VERSION ""

NS_ :

BS_:

BU_:

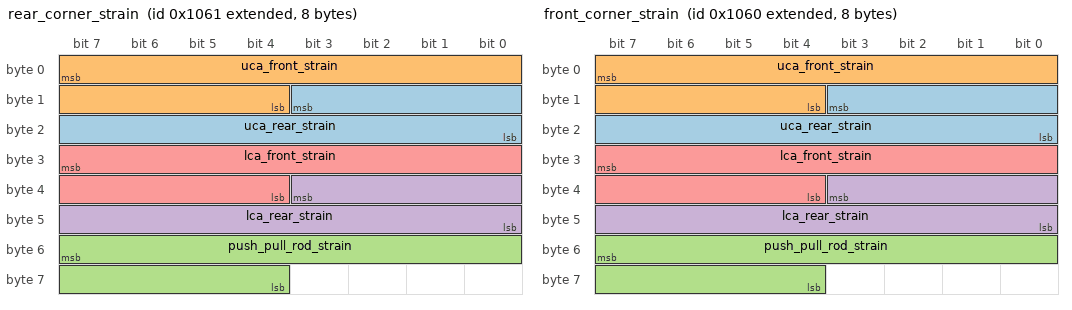
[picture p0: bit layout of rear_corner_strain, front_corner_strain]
BO_ 2147487841 rear_corner_strain: 8 Vector__XXX
 SG_ uca_rear_strain : 11|12@0+ (0.00488758553274682,0) [0|0] "V" Vector__XXX
 SG_ uca_front_strain : 7|12@0+ (0.00488758553274682,0) [0|0] "V" Vector__XXX
 SG_ push_pull_rod_strain : 55|12@0+ (0.00488758553274682,0) [0|0] "V" Vector__XXX
 SG_ lca_rear_strain : 35|12@0+ (0.00488758553274682,0) [0|0] "V" Vector__XXX
 SG_ lca_front_strain : 31|12@0+ (0.00488758553274682,0) [0|0] "V" Vector__XXX

BO_ 2147487840 front_corner_strain: 8 Vector__XXX
 SG_ uca_rear_strain : 11|12@0+ (0.00488758553274682,0) [0|0] "V" Vector__XXX
 SG_ uca_front_strain : 7|12@0+ (0.00488758553274682,0) [0|0] "V" Vector__XXX
 SG_ push_pull_rod_strain : 55|12@0+ (0.00488758553274682,0) [0|0] "V" Vector__XXX
 SG_ lca_rear_strain : 35|12@0+ (0.00488758553274682,0) [0|0] "V" Vector__XXX
 SG_ lca_front_strain : 31|12@0+ (0.00488758553274682,0) [0|0] "V" Vector__XXX

BA_DEF_  "BusType" STRING ;
BA_DEF_ BO_  "GenMsgCycleTime" INT 0 0;
BA_DEF_DEF_  "BusType" "CAN";
BA_DEF_DEF_  "GenMsgCycleTime" 0;
BA_ "GenMsgCycleTime" BO_ 2147487841 10;
BA_ "GenMsgCycleTime" BO_ 2147487840 10;
